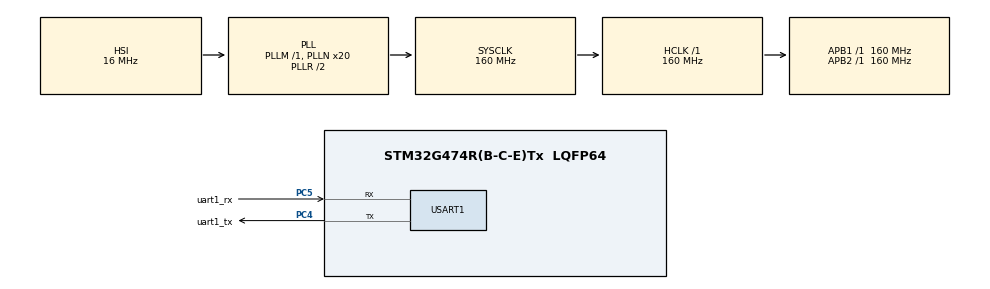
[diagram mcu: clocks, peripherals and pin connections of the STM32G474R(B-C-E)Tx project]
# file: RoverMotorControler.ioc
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IWDG.Prescaler=IWDG_PRESCALER_32
Mcu.Family=STM32G4
Mcu.Name=STM32G474R(B-C-E)Tx
Mcu.Package=LQFP64
NVIC.PriorityGroup=NVIC_PRIORITYGROUP_4
NVIC.USART1_IRQn=true\:7\:0\:true\:false\:true\:true\:true\:true
PA13.Mode=Serial_Wire
PA13.Signal=SYS_JTMS-SWDIO
PA14.Mode=Serial_Wire
PA14.Signal=SYS_JTCK-SWCLK
PC4.GPIO_Label=uart1_tx
PC4.Mode=Asynchronous
PC4.Signal=USART1_TX
PC5.GPIO_Label=uart1_rx
PC5.Mode=Asynchronous
PC5.Signal=USART1_RX
ProjectManager.HeapSize=0x200
ProjectManager.StackSize=0x400
ProjectManager.TargetToolchain=STM32CubeIDE
RCC.ADC12Freq_Value=160000000
RCC.ADC345Freq_Value=160000000
RCC.AHBFreq_Value=160000000
RCC.APB1Freq_Value=160000000
RCC.APB1TimFreq_Value=160000000
RCC.APB2Freq_Value=160000000
RCC.APB2TimFreq_Value=160000000
RCC.CortexFreq_Value=160000000
RCC.EXTERNAL_CLOCK_VALUE=12288000
RCC.HCLKFreq_Value=160000000
RCC.HSE_VALUE=8000000
RCC.HSI48_VALUE=48000000
RCC.HSI_VALUE=16000000
RCC.LSE_VALUE=32768
RCC.PLLN=20
RCC.SYSCLKFreq_VALUE=160000000
RCC.SYSCLKSource=RCC_SYSCLKSOURCE_PLLCLK
RCC.USBFreq_Value=160000000
RCC.VCOOutputFreq_Value=320000000
USART1.VirtualMode-Asynchronous=VM_ASYNC
VP_IWDG_VS_IWDG.Mode=IWDG_Activate
board=custom

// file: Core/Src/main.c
/* USER CODE BEGIN Header */
/**
  ******************************************************************************
  * @file           : main.c
  * @brief          : Main program body
  ******************************************************************************
  * @attention
  *
  * Copyright (c) 2022 STMicroelectronics.
  * All rights reserved.
  *
  * This software is licensed under terms that can be found in the LICENSE file
  * in the root directory of this software component.
  * If no LICENSE file comes with this software, it is provided AS-IS.
  *
  ******************************************************************************
  */
/* USER CODE END Header */
#include "main.h"

/* USER CODE BEGIN Includes */
#include "UART_Communication.h"
#include <stdio.h>
/* USER CODE END Includes */

/* USER CODE BEGIN PTD */

/*Enum to name "random values"*/
typedef enum  {
	FRAME_START = 0x3CU,

	MOTOR_SET_MODE = 0x11U,
	MOTOR_SET_SPEED = 0x12U,
	MOTOR_SET_POS = 0x13U
} BYTE_ID;
/* USER CODE END PTD */

IWDG_HandleTypeDef hiwdg;

UART_HandleTypeDef huart1;

/* USER CODE BEGIN PV */
/*handle for uart communication*/
UART_CommunicationTypeDef uart_communication;
/* USER CODE END PV */

void SystemClock_Config(void);
static void MX_GPIO_Init(void);
static void MX_USART1_UART_Init(void);
static void MX_IWDG_Init(void);

/* USER CODE BEGIN 0 */
/*
 * In my project I am using USART 1 connected to PC4(TX) and PC5(RX)
 * Debugger connected to and PA14 (SWCLK) and PA13 (SWDIO)
 * */

/******************************************************/
// MOTOR CALLBACKS
void motor_set_mode(uint8_t len, uint8_t* payload){
	//while testing it was causing issues like-hard stucking while sending multiple data
		//at once - most likely the issue is caused because of serial port converter -
		//some data is still being transfer to STM and STM tries to write data to ST-Link
		//the same data works good when testing callback with GPIO connected LED
	//for single-command test it works fine though
	//160Mhz seems to help the issue
	//printf("set_mode %i payload: %i\n", len, payload[0]);
}

void motor_set_speed(uint8_t len, uint8_t* payload){
	//while testing it was causing issues like-hard stucking while sending multiple data
		//at once - most likely the issue is caused because of serial port converter -
		//some data is still being transfer to STM and STM tries to write data to ST-Link
		//the same data works good when testing callback with GPIO connected LED
	//for single-command test it works fine though
	//160Mhz seems to help the issue
	//printf("set_speed %i payload: %i, %i, %i\n", len, payload[0], payload[1], payload[2]);
}

void motor_set_pos(uint8_t len, uint8_t* payload){
	//while testing it was causing issues like-hard stucking while sending multiple data
		//at once - most likely the issue is caused because of serial port converter -
		//some data is still being transfer to STM and STM tries to write data to ST-Link
		//the same data works good when testing callback with GPIO connected LED
	//for single-command test it works fine though
	//160Mhz seems to help the issue
	//printf("set_pos %i payload: %i, %i, %i, %i, %i\n", len, payload[0], payload[1], payload[2], payload[3], payload[4]);
}
/******************************************************/
/*
 * Callbacks for UART read and write
 * I have decided to define them outside of library because
 * those callback can be use to control different UARTs
 * so they shouldn't be defined inside library
 *
 * I have defined functions that should be called inside those
 * interrupt callbacks
 * */

void HAL_UART_RxCpltCallback(UART_HandleTypeDef *huart){
	if(huart == &huart1){
		UART_Communication_Receive_Interrupt_Callback(&uart_communication);
	}
}

void HAL_UART_TxCpltCallback(UART_HandleTypeDef *huart){
	if(huart == &huart1){
		UART_Communication_Transmit_Interrupt_Callback(&uart_communication);
	}
}

/* Same as with events, defining __io_put_char in library,
 * which defines how global printf() function works is not a good
 * idea, i have just created function that enables printf in my library */
int __io_putchar(int ch){
	UART_Communication__io_put_char(&uart_communication, ch);
	return 1;
}

/* USER CODE END 0 */

int main(void)
{

  /* MCU Configuration--------------------------------------------------------*/

  /* Reset of all peripherals, Initializes the Flash interface and the Systick. */
  HAL_Init();

  /* Configure the system clock */
  SystemClock_Config();

  /* Initialize all configured peripherals */
  MX_GPIO_Init();
  MX_USART1_UART_Init();
  MX_IWDG_Init();
  /* USER CODE BEGIN 2 */
  //Initialize my library
  if(UART_Communication_Init(&uart_communication, &huart1, FRAME_START, 80) != COMMUNICATION_OK)
  	  Error_Handler();

  //register all callbacks
  if(UART_Communication_Register_Callback(&uart_communication, MOTOR_SET_MODE, &motor_set_mode) != COMMUNICATION_OK)
  	  Error_Handler();
  if(UART_Communication_Register_Callback(&uart_communication, MOTOR_SET_SPEED, &motor_set_speed) != COMMUNICATION_OK)
	  Error_Handler();
  if(UART_Communication_Register_Callback(&uart_communication, MOTOR_SET_POS, &motor_set_pos) != COMMUNICATION_OK)
	  Error_Handler();

  /* USER CODE END 2 */

  /* Infinite loop */
  /* USER CODE BEGIN WHILE */
  while (1)
  {
	if(UART_Communication_Update(&uart_communication) == COMMUNICATION_HAL_ERROR)
		Error_Handler();
    /* USER CODE END WHILE */

    /* USER CODE BEGIN 3 */
  }

  /*
   * That is impossible to be called, but I just want to present
   * how to clean my uart library - it will have use when we implement some
   * kind of exit from above loop
   * */
  UART_Communication_Clean(&uart_communication);
  /* USER CODE END 3 */
}

void SystemClock_Config(void)
{
  RCC_OscInitTypeDef RCC_OscInitStruct = {0};
  RCC_ClkInitTypeDef RCC_ClkInitStruct = {0};

  /** Configure the main internal regulator output voltage
  */
  HAL_PWREx_ControlVoltageScaling(PWR_REGULATOR_VOLTAGE_SCALE1_BOOST);

  /** Initializes the RCC Oscillators according to the specified parameters
  * in the RCC_OscInitTypeDef structure.
  */
  RCC_OscInitStruct.OscillatorType = RCC_OSCILLATORTYPE_HSI|RCC_OSCILLATORTYPE_LSI;
  RCC_OscInitStruct.HSIState = RCC_HSI_ON;
  RCC_OscInitStruct.HSICalibrationValue = RCC_HSICALIBRATION_DEFAULT;
  RCC_OscInitStruct.LSIState = RCC_LSI_ON;
  RCC_OscInitStruct.PLL.PLLState = RCC_PLL_ON;
  RCC_OscInitStruct.PLL.PLLSource = RCC_PLLSOURCE_HSI;
  RCC_OscInitStruct.PLL.PLLM = RCC_PLLM_DIV1;
  RCC_OscInitStruct.PLL.PLLN = 20;
  RCC_OscInitStruct.PLL.PLLP = RCC_PLLP_DIV2;
  RCC_OscInitStruct.PLL.PLLQ = RCC_PLLQ_DIV2;
  RCC_OscInitStruct.PLL.PLLR = RCC_PLLR_DIV2;
  if (HAL_RCC_OscConfig(&RCC_OscInitStruct) != HAL_OK)
  {
    Error_Handler();
  }

  /** Initializes the CPU, AHB and APB buses clocks
  */
  RCC_ClkInitStruct.ClockType = RCC_CLOCKTYPE_HCLK|RCC_CLOCKTYPE_SYSCLK
                              |RCC_CLOCKTYPE_PCLK1|RCC_CLOCKTYPE_PCLK2;
  RCC_ClkInitStruct.SYSCLKSource = RCC_SYSCLKSOURCE_PLLCLK;
  RCC_ClkInitStruct.AHBCLKDivider = RCC_SYSCLK_DIV1;
  RCC_ClkInitStruct.APB1CLKDivider = RCC_HCLK_DIV1;
  RCC_ClkInitStruct.APB2CLKDivider = RCC_HCLK_DIV1;

  if (HAL_RCC_ClockConfig(&RCC_ClkInitStruct, FLASH_LATENCY_4) != HAL_OK)
  {
    Error_Handler();
  }
}

static void MX_IWDG_Init(void)
{

  hiwdg.Instance = IWDG;
  hiwdg.Init.Prescaler = IWDG_PRESCALER_32;
  hiwdg.Init.Window = 4095;
  hiwdg.Init.Reload = 4095;
  if (HAL_IWDG_Init(&hiwdg) != HAL_OK)
  {
    Error_Handler();
  }

}

static void MX_USART1_UART_Init(void)
{

  huart1.Instance = USART1;
  huart1.Init.BaudRate = 115200;
  huart1.Init.WordLength = UART_WORDLENGTH_8B;
  huart1.Init.StopBits = UART_STOPBITS_1;
  huart1.Init.Parity = UART_PARITY_NONE;
  huart1.Init.Mode = UART_MODE_TX_RX;
  huart1.Init.HwFlowCtl = UART_HWCONTROL_NONE;
  huart1.Init.OverSampling = UART_OVERSAMPLING_16;
  huart1.Init.OneBitSampling = UART_ONE_BIT_SAMPLE_DISABLE;
  huart1.Init.ClockPrescaler = UART_PRESCALER_DIV1;
  huart1.AdvancedInit.AdvFeatureInit = UART_ADVFEATURE_NO_INIT;
  if (HAL_UART_Init(&huart1) != HAL_OK)
  {
    Error_Handler();
  }
  if (HAL_UARTEx_SetTxFifoThreshold(&huart1, UART_TXFIFO_THRESHOLD_1_8) != HAL_OK)
  {
    Error_Handler();
  }
  if (HAL_UARTEx_SetRxFifoThreshold(&huart1, UART_RXFIFO_THRESHOLD_1_8) != HAL_OK)
  {
    Error_Handler();
  }
  if (HAL_UARTEx_DisableFifoMode(&huart1) != HAL_OK)
  {
    Error_Handler();
  }

}

static void MX_GPIO_Init(void)
{

  /* GPIO Ports Clock Enable */
  __HAL_RCC_GPIOC_CLK_ENABLE();
  __HAL_RCC_GPIOA_CLK_ENABLE();

}

void Error_Handler(void)
{
  __disable_irq();
  while (1)
  {
  }
}
